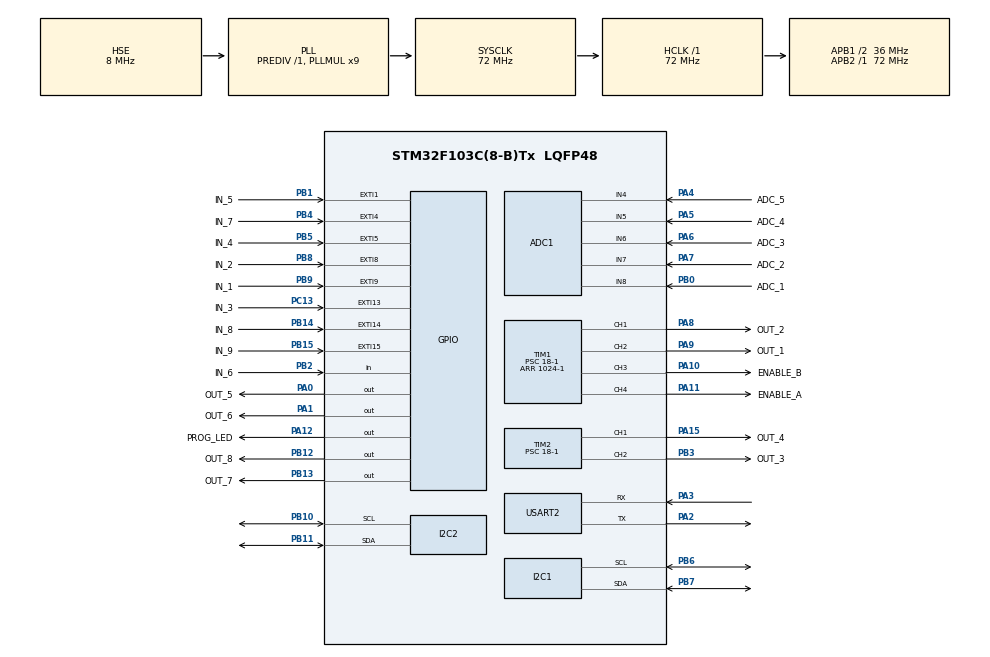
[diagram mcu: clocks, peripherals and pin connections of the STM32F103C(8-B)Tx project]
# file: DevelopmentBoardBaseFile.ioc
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ADC1.Channel-0\#ChannelRegularConversion=ADC_CHANNEL_4
ADC1.Channel-1\#ChannelRegularConversion=ADC_CHANNEL_5
ADC1.Channel-2\#ChannelRegularConversion=ADC_CHANNEL_6
ADC1.Channel-3\#ChannelRegularConversion=ADC_CHANNEL_7
ADC1.Channel-4\#ChannelRegularConversion=ADC_CHANNEL_8
ADC1.ContinuousConvMode=ENABLE
ADC1.NbrOfConversion=5
ADC1.NbrOfConversionFlag=1
ADC1.Rank-0\#ChannelRegularConversion=1
ADC1.Rank-1\#ChannelRegularConversion=2
ADC1.Rank-2\#ChannelRegularConversion=3
ADC1.Rank-3\#ChannelRegularConversion=4
ADC1.Rank-4\#ChannelRegularConversion=5
ADC1.SamplingTime-0\#ChannelRegularConversion=ADC_SAMPLETIME_239CYCLES_5
ADC1.SamplingTime-1\#ChannelRegularConversion=ADC_SAMPLETIME_239CYCLES_5
ADC1.SamplingTime-2\#ChannelRegularConversion=ADC_SAMPLETIME_239CYCLES_5
ADC1.SamplingTime-3\#ChannelRegularConversion=ADC_SAMPLETIME_239CYCLES_5
ADC1.SamplingTime-4\#ChannelRegularConversion=ADC_SAMPLETIME_239CYCLES_5
ADC1.master=1
Dma.ADC1.0.Direction=DMA_PERIPH_TO_MEMORY
Dma.ADC1.0.Instance=DMA1_Channel1
Dma.ADC1.0.MemDataAlignment=DMA_MDATAALIGN_HALFWORD
Dma.ADC1.0.MemInc=DMA_MINC_ENABLE
Dma.ADC1.0.Mode=DMA_CIRCULAR
Dma.ADC1.0.PeriphDataAlignment=DMA_PDATAALIGN_HALFWORD
Dma.ADC1.0.PeriphInc=DMA_PINC_DISABLE
Dma.ADC1.0.Priority=DMA_PRIORITY_LOW
Dma.I2C1_RX.1.Direction=DMA_PERIPH_TO_MEMORY
Dma.I2C1_RX.1.Instance=DMA1_Channel7
Dma.I2C1_RX.1.MemDataAlignment=DMA_MDATAALIGN_BYTE
Dma.I2C1_RX.1.MemInc=DMA_MINC_ENABLE
Dma.I2C1_RX.1.Mode=DMA_NORMAL
Dma.I2C1_RX.1.PeriphDataAlignment=DMA_PDATAALIGN_BYTE
Dma.I2C1_RX.1.PeriphInc=DMA_PINC_DISABLE
Dma.I2C1_RX.1.Priority=DMA_PRIORITY_LOW
Dma.I2C1_TX.2.Direction=DMA_MEMORY_TO_PERIPH
Dma.I2C1_TX.2.Instance=DMA1_Channel6
Dma.I2C1_TX.2.MemDataAlignment=DMA_MDATAALIGN_BYTE
Dma.I2C1_TX.2.MemInc=DMA_MINC_ENABLE
Dma.I2C1_TX.2.Mode=DMA_NORMAL
Dma.I2C1_TX.2.PeriphDataAlignment=DMA_PDATAALIGN_BYTE
Dma.I2C1_TX.2.PeriphInc=DMA_PINC_DISABLE
Dma.I2C1_TX.2.Priority=DMA_PRIORITY_LOW
Dma.I2C2_RX.3.Direction=DMA_PERIPH_TO_MEMORY
Dma.I2C2_RX.3.Instance=DMA1_Channel5
Dma.I2C2_RX.3.MemDataAlignment=DMA_MDATAALIGN_BYTE
Dma.I2C2_RX.3.MemInc=DMA_MINC_ENABLE
Dma.I2C2_RX.3.Mode=DMA_NORMAL
Dma.I2C2_RX.3.PeriphDataAlignment=DMA_PDATAALIGN_BYTE
Dma.I2C2_RX.3.PeriphInc=DMA_PINC_DISABLE
Dma.I2C2_RX.3.Priority=DMA_PRIORITY_LOW
Dma.I2C2_TX.4.Direction=DMA_MEMORY_TO_PERIPH
Dma.I2C2_TX.4.Instance=DMA1_Channel4
Dma.I2C2_TX.4.MemDataAlignment=DMA_MDATAALIGN_BYTE
Dma.I2C2_TX.4.MemInc=DMA_MINC_ENABLE
Dma.I2C2_TX.4.Mode=DMA_NORMAL
Dma.I2C2_TX.4.PeriphDataAlignment=DMA_PDATAALIGN_BYTE
Dma.I2C2_TX.4.PeriphInc=DMA_PINC_DISABLE
Dma.I2C2_TX.4.Priority=DMA_PRIORITY_LOW
Dma.Request0=ADC1
Dma.Request1=I2C1_RX
Dma.Request2=I2C1_TX
Dma.Request3=I2C2_RX
Dma.Request4=I2C2_TX
IWDG.Prescaler=IWDG_PRESCALER_32
Mcu.Family=STM32F1
Mcu.Name=STM32F103C(8-B)Tx
Mcu.Package=LQFP48
NVIC.DMA1_Channel1_IRQn=true\:0\:0\:false\:false\:true\:false\:true
NVIC.DMA1_Channel4_IRQn=true\:0\:0\:false\:false\:true\:false\:true
NVIC.DMA1_Channel5_IRQn=true\:0\:0\:false\:false\:true\:false\:true
NVIC.DMA1_Channel6_IRQn=true\:0\:0\:false\:false\:true\:false\:true
NVIC.DMA1_Channel7_IRQn=true\:0\:0\:false\:false\:true\:false\:true
NVIC.EXTI15_10_IRQn=true\:0\:0\:false\:false\:true\:true\:true
NVIC.EXTI1_IRQn=true\:0\:0\:false\:false\:true\:true\:true
NVIC.EXTI9_5_IRQn=true\:0\:0\:false\:false\:true\:true\:true
NVIC.PVD_IRQn=true\:0\:0\:false\:false\:true\:true\:true
NVIC.PriorityGroup=NVIC_PRIORITYGROUP_4
NVIC.TIM1_UP_IRQn=true\:0\:0\:false\:false\:true\:true\:true
NVIC.TIM3_IRQn=true\:0\:0\:false\:false\:true\:true\:true
PA0-WKUP.GPIO_Label=OUT_5
PA0-WKUP.Signal=GPIO_Output
PA1.GPIO_Label=OUT_6
PA1.Signal=GPIO_Output
PA10.GPIO_Label=ENABLE_B
PA10.Signal=S_TIM1_CH3
PA11.GPIO_Label=ENABLE_A
PA11.Signal=S_TIM1_CH4
PA12.GPIO_Label=PROG_LED
PA12.GPIO_PuPd=GPIO_NOPULL
PA12.Signal=GPIO_Output
PA13.Mode=Serial_Wire
PA13.Signal=SYS_JTMS-SWDIO
PA14.Mode=Serial_Wire
PA14.Signal=SYS_JTCK-SWCLK
PA15.GPIO_Label=OUT_4
PA15.Signal=S_TIM2_CH1_ETR
PA2.Mode=Asynchronous
PA2.Signal=USART2_TX
PA3.Mode=Asynchronous
PA3.Signal=USART2_RX
PA4.GPIO_Label=ADC_5
PA4.Signal=ADCx_IN4
PA5.GPIO_Label=ADC_4
PA5.Signal=ADCx_IN5
PA6.GPIO_Label=ADC_3
PA6.Signal=ADCx_IN6
PA7.GPIO_Label=ADC_2
PA7.Signal=ADCx_IN7
PA8.GPIO_Label=OUT_2
PA8.Signal=S_TIM1_CH1
PA9.GPIO_Label=OUT_1
PA9.Signal=S_TIM1_CH2
PB0.GPIO_Label=ADC_1
PB0.Signal=ADCx_IN8
PB1.GPIO_Label=IN_5
PB1.Signal=GPXTI1
PB10.Mode=I2C
PB10.Signal=I2C2_SCL
PB11.Mode=I2C
PB11.Signal=I2C2_SDA
PB12.GPIO_Label=OUT_8
PB12.GPIO_PuPd=GPIO_NOPULL
PB12.Signal=GPIO_Output
PB13.GPIO_Label=OUT_7
PB13.GPIO_PuPd=GPIO_NOPULL
PB13.Signal=GPIO_Output
PB14.GPIO_Label=IN_8
PB14.Signal=GPXTI14
PB15.GPIO_Label=IN_9
PB15.Signal=GPXTI15
PB2.GPIO_Label=IN_6
PB2.GPIO_PuPd=GPIO_PULLUP
PB2.Signal=GPIO_Input
PB3.GPIO_Label=OUT_3
PB3.Signal=S_TIM2_CH2
PB4.GPIO_Label=IN_7
PB4.Signal=GPXTI4
PB5.GPIO_Label=IN_4
PB5.Signal=GPXTI5
PB6.Mode=I2C
PB6.Signal=I2C1_SCL
PB7.Mode=I2C
PB7.Signal=I2C1_SDA
PB8.GPIO_Label=IN_2
PB8.GPIO_ModeDefaultEXTI=GPIO_MODE_IT_FALLING
PB8.Signal=GPXTI8
PB9.GPIO_Label=IN_1
PB9.Signal=GPXTI9
PC13-TAMPER-RTC.GPIO_Label=IN_3
PC13-TAMPER-RTC.Signal=GPXTI13
PC14-OSC32_IN.Mode=LSE-External-Oscillator
PC14-OSC32_IN.Signal=RCC_OSC32_IN
PC15-OSC32_OUT.Mode=LSE-External-Oscillator
PC15-OSC32_OUT.Signal=RCC_OSC32_OUT
PD0-OSC_IN.Mode=HSE-External-Oscillator
PD0-OSC_IN.Signal=RCC_OSC_IN
PD1-OSC_OUT.Mode=HSE-External-Oscillator
PD1-OSC_OUT.Signal=RCC_OSC_OUT
ProjectManager.HeapSize=0x200
ProjectManager.StackSize=0x400
ProjectManager.TargetToolchain=STM32CubeIDE
RCC.ADCPresc=RCC_ADCPCLK2_DIV6
RCC.AHBFreq_Value=72000000
RCC.APB1CLKDivider=RCC_HCLK_DIV2
RCC.APB1Freq_Value=36000000
RCC.APB1TimFreq_Value=72000000
RCC.APB2Freq_Value=72000000
RCC.APB2TimFreq_Value=72000000
RCC.HCLKFreq_Value=72000000
RCC.PLLMUL=RCC_PLL_MUL9
RCC.PLLSourceVirtual=RCC_PLLSOURCE_HSE
RCC.SYSCLKFreq_VALUE=72000000
RCC.SYSCLKSource=RCC_SYSCLKSOURCE_PLLCLK
RCC.USBFreq_Value=72000000
SH.ADCx_IN4.0=ADC1_IN4,IN4
SH.ADCx_IN5.0=ADC1_IN5,IN5
SH.ADCx_IN6.0=ADC1_IN6,IN6
SH.ADCx_IN7.0=ADC1_IN7,IN7
SH.ADCx_IN8.0=ADC1_IN8,IN8
SH.S_TIM1_CH1.0=TIM1_CH1,PWM Generation1 CH1
SH.S_TIM1_CH2.0=TIM1_CH2,PWM Generation2 CH2
SH.S_TIM1_CH3.0=TIM1_CH3,PWM Generation3 CH3
SH.S_TIM1_CH4.0=TIM1_CH4,PWM Generation4 CH4
SH.S_TIM2_CH1_ETR.0=TIM2_CH1,PWM Generation1 CH1
SH.S_TIM2_CH2.0=TIM2_CH2,PWM Generation2 CH2
TIM1.Channel-PWM\ Generation1\ CH1=TIM_CHANNEL_1
TIM1.Channel-PWM\ Generation2\ CH2=TIM_CHANNEL_2
TIM1.Channel-PWM\ Generation3\ CH3=TIM_CHANNEL_3
TIM1.Channel-PWM\ Generation4\ CH4=TIM_CHANNEL_4
TIM1.OCFastMode_PWM-PWM\ Generation1\ CH1=TIM_OCFAST_ENABLE
TIM1.OCFastMode_PWM-PWM\ Generation2\ CH2=TIM_OCFAST_ENABLE
TIM1.OCFastMode_PWM-PWM\ Generation3\ CH3=TIM_OCFAST_ENABLE
TIM1.OCFastMode_PWM-PWM\ Generation4\ CH4=TIM_OCFAST_ENABLE
TIM1.Period=1024-1
TIM1.Prescaler=18-1
TIM1.Pulse-PWM\ Generation2\ CH2=0
TIM1.Pulse-PWM\ Generation3\ CH3=0
TIM1.Pulse-PWM\ Generation4\ CH4=0
TIM2.Channel-PWM\ Generation1\ CH1=TIM_CHANNEL_1
TIM2.Channel-PWM\ Generation2\ CH2=TIM_CHANNEL_2
TIM2.OCFastMode_PWM-PWM\ Generation1\ CH1=TIM_OCFAST_ENABLE
TIM2.OCFastMode_PWM-PWM\ Generation2\ CH2=TIM_OCFAST_ENABLE
TIM2.Period=1024-1
TIM2.Prescaler=18-1
TIM3.Period=10000-1
TIM3.Prescaler=7200-1
USART2.VirtualMode=VM_ASYNC
VP_IWDG_VS_IWDG.Mode=IWDG_Activate
VP_TIM1_VS_ClockSourceINT.Mode=Internal
VP_TIM2_VS_ClockSourceINT.Mode=Internal
VP_TIM3_VS_ClockSourceINT.Mode=Internal
VP_TIM4_VS_ClockSourceINT.Mode=Internal
board=custom

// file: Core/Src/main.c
/* USER CODE BEGIN Header */
/**
  ******************************************************************************
  * @file           : main.c
  * @brief          : Main program body
  ******************************************************************************
  * @attention
  *
  * <h2><center>&copy; Copyright (c) 2020 STMicroelectronics.
  * All rights reserved.</center></h2>
  *
  * This software component is licensed by ST under BSD 3-Clause license,
  * the "License"; You may not use this file except in compliance with the
  * License. You may obtain a copy of the License at:
  *                        opensource.org/licenses/BSD-3-Clause
  *
  ******************************************************************************
  */
/* USER CODE END Header */

#include "main.h"
#include "adc.h"
#include "dma.h"
#include "i2c.h"
#include "iwdg.h"
#include "tim.h"
#include "usart.h"
#include "gpio.h"

/* USER CODE BEGIN Includes */
#include "init.h"
#include "application.h"
#include "MotorDriver.h"

/* USER CODE END Includes */

void SystemClock_Config(void);

int main(void)
{

  /* MCU Configuration--------------------------------------------------------*/

  /* Reset of all peripherals, Initializes the Flash interface and the Systick. */
  HAL_Init();

  /* Configure the system clock */
  SystemClock_Config();

  /* Initialize all configured peripherals */
  MX_GPIO_Init();
  MX_DMA_Init();
  MX_ADC1_Init();
  MX_I2C1_Init();
  MX_I2C2_Init();
  MX_TIM1_Init();
  MX_TIM2_Init();
  MX_USART2_UART_Init();
  MX_TIM3_Init();
  MX_TIM4_Init();
 //MX_IWDG_Init();
  /* USER CODE BEGIN 2 */
  DevBoardInit();
  //WatchDogHandler();
  /* USER CODE END 2 */

  /* Infinite loop */
  while (1)
  {

    /* USER CODE BEGIN 3 */
	  application();
	//HelloWatchDog();
	  StepperController(StepperState(1));	// Running stepper controller 1
  }
  /* USER CODE END 3 */
}

void SystemClock_Config(void)
{
  RCC_OscInitTypeDef RCC_OscInitStruct = {0};
  RCC_ClkInitTypeDef RCC_ClkInitStruct = {0};
  RCC_PeriphCLKInitTypeDef PeriphClkInit = {0};

  /** Initializes the CPU, AHB and APB busses clocks
  */
  RCC_OscInitStruct.OscillatorType = RCC_OSCILLATORTYPE_LSI|RCC_OSCILLATORTYPE_HSE;
  RCC_OscInitStruct.HSEState = RCC_HSE_ON;
  RCC_OscInitStruct.HSEPredivValue = RCC_HSE_PREDIV_DIV1;
  RCC_OscInitStruct.HSIState = RCC_HSI_ON;
  RCC_OscInitStruct.LSIState = RCC_LSI_ON;
  RCC_OscInitStruct.PLL.PLLState = RCC_PLL_ON;
  RCC_OscInitStruct.PLL.PLLSource = RCC_PLLSOURCE_HSE;
  RCC_OscInitStruct.PLL.PLLMUL = RCC_PLL_MUL9;
  if (HAL_RCC_OscConfig(&RCC_OscInitStruct) != HAL_OK)
  {
    Error_Handler();
  }
  /** Initializes the CPU, AHB and APB busses clocks
  */
  RCC_ClkInitStruct.ClockType = RCC_CLOCKTYPE_HCLK|RCC_CLOCKTYPE_SYSCLK
                              |RCC_CLOCKTYPE_PCLK1|RCC_CLOCKTYPE_PCLK2;
  RCC_ClkInitStruct.SYSCLKSource = RCC_SYSCLKSOURCE_PLLCLK;
  RCC_ClkInitStruct.AHBCLKDivider = RCC_SYSCLK_DIV1;
  RCC_ClkInitStruct.APB1CLKDivider = RCC_HCLK_DIV2;
  RCC_ClkInitStruct.APB2CLKDivider = RCC_HCLK_DIV1;

  if (HAL_RCC_ClockConfig(&RCC_ClkInitStruct, FLASH_LATENCY_2) != HAL_OK)
  {
    Error_Handler();
  }
  PeriphClkInit.PeriphClockSelection = RCC_PERIPHCLK_ADC;
  PeriphClkInit.AdcClockSelection = RCC_ADCPCLK2_DIV6;
  if (HAL_RCCEx_PeriphCLKConfig(&PeriphClkInit) != HAL_OK)
  {
    Error_Handler();
  }
}

void Error_Handler(void)
{
}

/************************ (C) COPYRIGHT STMicroelectronics *****END OF FILE****/
